# STM32U545 register map
File version: 1.0
CPU: CM33 r0p1, little endian, MPU, FPU, 4 interrupt priority bits
Registers are 32-bit, read-write, reset 0x0 unless marked. A register's access mark holds for its fields unless they carry their own. Offsets are from the block's base; [hi:lo] are bit positions; {n}, {i} and the like mark numbered series; 'fields as' and 'values as' point back to an identical list.

## DAC1 — Digital-to-analog converter
Base 0x46021800
Same registers: SEC_DAC1 0x56021800
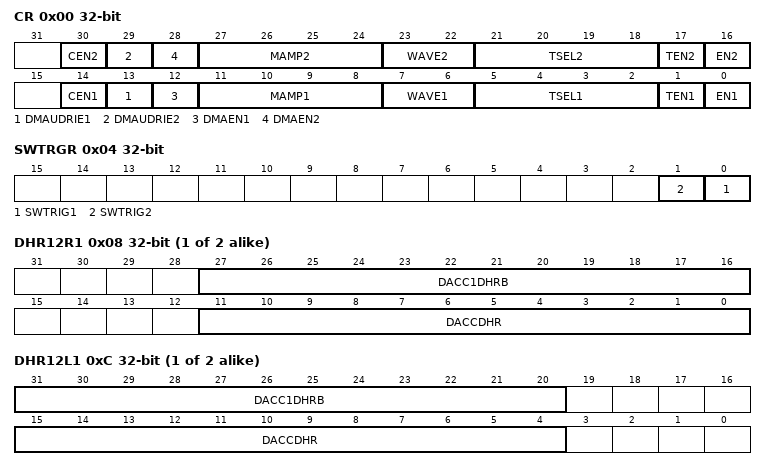
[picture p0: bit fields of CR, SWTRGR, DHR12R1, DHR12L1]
0x00 CR — DAC control register
  [21:18] TSEL2 — DAC channel2 trigger selection
    0=Swtrig (Software trigger); 1=Tim1Trgo (Timer 1 TRGO event); 2=Tim2Trgo (Timer 2 TRGO event); {v}=Tim{v+1}Trgo (Timer {v+1} TRGO event) (v=3..7); 8=Tim15Trgo (Timer 15 TRGO event); 11=LPTIM1 CH1 event; 12=LPTIM3 CH1 event; 13=Exti9 (EXTI line 9)
  [16n-2] CEN{n} (n=1..2) — DAC channel{n} calibration enable
    0=Normal (DAC Channel X Normal operating mode); 1=Calibration (DAC Channel X calibration mode)
  [16n-3] DMAUDRIE{n} (n=1..2) — DAC channel{n} DMA Underrun Interrupt enable
    0=Disabled (DAC channel X DMA Underrun Interrupt disabled); 1=Enabled (DAC channel X DMA Underrun Interrupt enabled)
  [16n-4] DMAEN{n} (n=1..2) — DAC channel{n} DMA enable
    0=Disabled (DAC Channel X DMA mode disabled); 1=Enabled (DAC Channel X DMA mode enabled)
  [16n-5:16n-8] MAMP{n} (n=1..2) — DAC channel{n} mask/amplitude selector
    0=Amp1 (Unmask bit0 of LFSR/ triangle amplitude equal to 1); 1=Amp3 (Unmask bits[1:0] of LFSR/ triangle amplitude equal to 3); 2=Amp7 (Unmask bits[2:0] of LFSR/ triangle amplitude equal to 7); 3=Amp15 (Unmask bits[3:0] of LFSR/ triangle amplitude equal to 15); 4=Amp31 (Unmask bits[4:0] of LFSR/ triangle amplitude equal to 31); 5=Amp63 (Unmask bits[5:0] of LFSR/ triangle amplitude equal 63); 6=Amp127 (Unmask bits[6:0] of LFSR/ triangle amplitude equal to 127); 7=Amp255 (Unmask bits[7:0] of LFSR/ triangle amplitude equal to 255); 8=Amp511 (Unmask bits[8:0] of LFSR/ triangle amplitude equal to 511); 9=Amp1023 (Unmask bits[9:0] of LFSR/ triangle amplitude equal to 1023); 10=Amp2047 (Unmask bits[10:0] of LFSR/ triangle amplitude equal to 2047); other=Amp4095 (Unmask bits[11:0] of LFSR/ triangle amplitude equal to 4095)
  [16n-9:16n-10] WAVE{n} (n=1..2) — DAC channel{n} noise/triangle wave generation enable
    0=Disabled (Wave generation disabled); 1=Noise wave generation enabled; other=Triangle wave generation enabled
  [5:2] TSEL1 — DAC channel1 trigger selection
    values as TSEL2
  [16n-15] TEN{n} (n=1..2) — DAC channel{n} trigger enable
    0=Disabled (DAC Channel X trigger disabled); 1=Enabled (DAC Channel X trigger enabled)
  [16n-16] EN{n} (n=1..2) — DAC channel{n} enable
    0=Disabled (DAC Channel X disabled); 1=Enabled (DAC Channel X enabled)
0x04 SWTRGR wo — DAC software trigger register
  [n-1] SWTRIG{n} (n=1..2) — DAC channel{n} software trigger
    0=NoTrigger; 1=Trigger
0x08 DHR12R{i} (i=1..2; step 0xC) — channel{i} 12-bit right-aligned data holding register
  [27:16] DACC1DHRB — DAC channel1 12-bit right-aligned data B
  [11:0] DACCDHR — DAC channel1 12-bit right-aligned data
{0x0+0xC*i} DHR12L{i} (i=1..2) — channel{i} 12-bit left aligned data holding register
  [31:20] DACC1DHRB — DAC channel1 12-bit left-aligned data B
  [15:4] DACCDHR — DAC channel1 12-bit left-aligned data
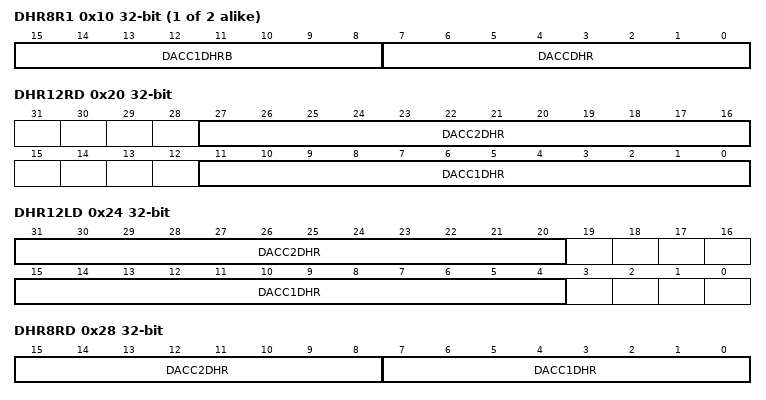
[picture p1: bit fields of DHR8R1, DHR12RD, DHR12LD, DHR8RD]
{0x4+0xC*i} DHR8R{i} (i=1..2) — channel{i} 8-bit right aligned data holding register
  [15:8] DACC1DHRB — DAC channel1 8-bit right-aligned Sdata
  [7:0] DACCDHR — DAC channel1 8-bit right-aligned data
0x20 DHR12RD — Dual DAC 12-bit right-aligned data holding register
  [16n-5:16n-16] DACC{n}DHR (n=1..2) — DAC channel{n} 12-bit right-aligned data
0x24 DHR12LD — DUAL DAC 12-bit left aligned data holding register
  [16n-1:16n-12] DACC{n}DHR (n=1..2) — DAC channel{n} 12-bit left-aligned data
0x28 DHR8RD — DUAL DAC 8-bit right aligned data holding register
  [8n-1:8n-8] DACC{n}DHR (n=1..2) — DAC channel{n} 8-bit right-aligned data
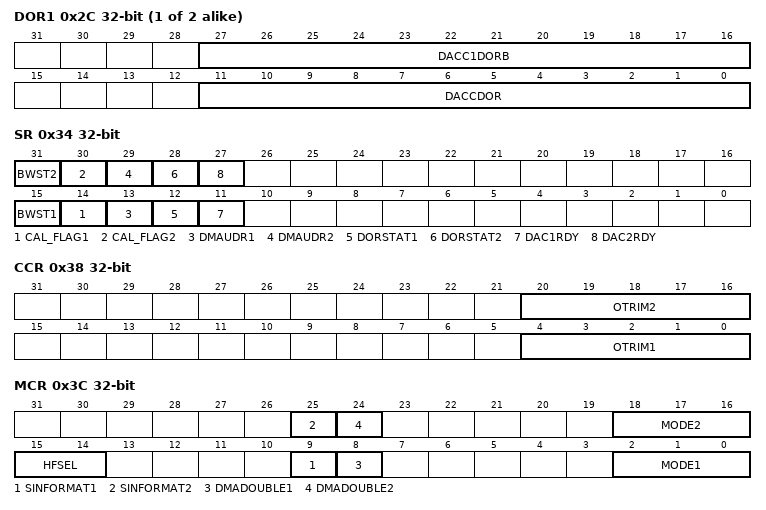
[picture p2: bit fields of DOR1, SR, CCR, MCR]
{0x28+4i} DOR{i} (i=1..2) ro — channel{i} data output register
  [27:16] DACC1DORB — DAC channel1 data output
  [11:0] DACCDOR — DAC channel1 data output
0x34 SR access per field — DAC status register
  [16n-1] BWST{n} (n=1..2) ro — DAC channel{n} busy writing sample time flag
    0=Idle (There is no write operation of DAC_SHSR1 ongoing: DAC_SHSR1 can be written); 1=Busy (There is a write operation of DAC_SHSR1 ongoing: DAC_SHSR1 cannot be written)
  [16n-2] CAL_FLAG{n} (n=1..2) ro — DAC channel{n} calibration offset status
    0=Lower (Calibration trimming value is lower than the offset correction value); 1=Equal_Higher (Calibration trimming value is equal or greater than the offset correction value)
  [16n-3] DMAUDR{n} (n=1..2) rw — DAC channel{n} DMA underrun flag
    0=NoUnderrun (No DMA underrun error condition occurred for DAC channel x); 1=Underrun (DMA underrun error condition occurred for DAC channel x (the currently selected trigger is driving DAC channel1 conversion at a frequency higher than the DMA service capability rate))
  [16n-4] DORSTAT{n} (n=1..2) ro — DAC channel{n} output register status bit
    0=Dor (DOR[11:0] is used actual DAC output); 1=DORB[11:0] is used actual DAC output
  [16n-5] DAC{n}RDY (n=1..2) ro — DAC channel{n} ready status bit
    0=NotReady (DAC channelX is not yet ready to accept the trigger nor output data); 1=Ready (DAC channelX is ready to accept the trigger or output data)
0x38 CCR — DAC calibration control register
  [16n-12:16n-16] OTRIM{n} (n=1..2) — DAC channel{n} offset trimming value
0x3C MCR — DAC mode control register
  [15:14] HFSEL — High frequency interface mode selection
    0=Disabled (High frequency interface mode disabled); 1=More80Mhz (High frequency interface mode enabled for AHB clock frequency > 80 MHz); 2=More160Mhz (High frequency interface mode enabled for AHB clock frequency >160 MHz)
  [16n-7] SINFORMAT{n} (n=1..2) — Enable signed format for DAC channel{n}
    0=Unsigned (Input data is in unsigned format); 1=Signed (Input data is in signed format (2's complement). The MSB bit represents the sign.)
  [16n-8] DMADOUBLE{n} (n=1..2) — DAC channel{n} DMA double data mode
    0=Normal (DMA Normal mode selected); 1=DoubleData (DMA Double data mode selected)
  [16n-14:16n-16] MODE{n} (n=1..2) — DAC channel{n} mode
    0=NormalPinBuffer (Normal mode - DAC channelx is connected to external pin with Buffer enabled); 1=NormalPinChipBuffer (Normal mode - DAC channelx is connected to external pin and to on chip peripherals with Buffer enabled); 2=NormalPinNoBuffer (Normal mode - DAC channelx is connected to external pin with Buffer disabled); 3=NormalChipNoBuffer (Normal mode - DAC channelx is connected to on chip peripherals with Buffer disabled); 4=SHPinBuffer (S&H mode - DAC channelx is connected to external pin with Buffer enabled); 5=SHPinChipBuffer (S&H mode - DAC channelx is connected to external pin and to on chip peripherals with Buffer enabled); 6=SHPinNoBuffer (S&H mode - DAC channelx is connected to external pin and to on chip peripherals with Buffer disabled); 7=SHChipNoBuffer (S&H mode - DAC channelx is connected to on chip peripherals with Buffer disabled)
{0x3C+4i} SHSR{i} (i=1..2) — DAC channel{i} sample and hold sample time register
  [9:0] TSAMPLE — DAC Channel 1 sample Time (only valid in sample & hold mode)
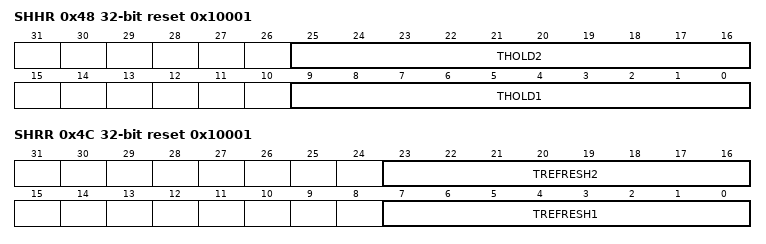
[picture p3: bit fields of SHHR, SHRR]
0x48 SHHR reset 0x10001 — DAC Sample and Hold hold time register
  [16n-7:16n-16] THOLD{n} (n=1..2) — DAC channel{n} hold time (only valid in Sample and hold mode)
0x4C SHRR reset 0x10001 — DAC Sample and Hold refresh time register
  [16n-9:16n-16] TREFRESH{n} (n=1..2) — DAC channel{n} refresh time (only valid in Sample and hold mode)
0x54 AUTOCR — Autonomous mode control register
  [22] AUTOMODE — DAC Autonomous mode
    0=Disabled (DAC Autonomous mode disabled); 1=Enabled (DAC Autonomous mode enabled)
